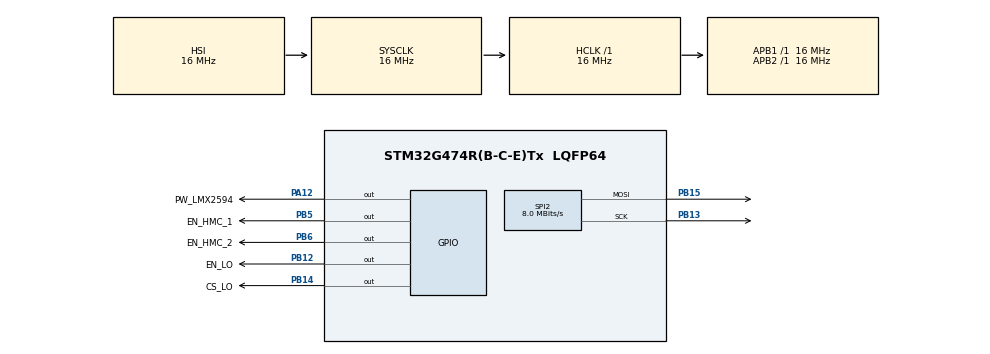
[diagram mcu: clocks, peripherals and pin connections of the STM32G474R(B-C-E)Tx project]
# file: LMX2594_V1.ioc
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Mcu.Family=STM32G4
Mcu.Name=STM32G474R(B-C-E)Tx
Mcu.Package=LQFP64
NVIC.PriorityGroup=NVIC_PRIORITYGROUP_4
PA12.GPIO_Label=PW_LMX2594
PA12.Signal=GPIO_Output
PA13.Mode=JTAG_5_pins
PA13.Signal=SYS_JTMS-SWDIO
PA14.Mode=JTAG_5_pins
PA14.Signal=SYS_JTCK-SWCLK
PA15.Mode=JTAG_5_pins
PA15.Signal=SYS_JTDI
PB12.GPIO_Label=EN_LO
PB12.GPIO_Speed=GPIO_SPEED_FREQ_HIGH
PB12.Signal=GPIO_Output
PB13.Mode=TX_Only_Simplex_Unidirect_Master
PB13.Signal=SPI2_SCK
PB14.GPIO_Label=CS_LO
PB14.GPIO_Speed=GPIO_SPEED_FREQ_HIGH
PB14.Signal=GPIO_Output
PB15.Mode=TX_Only_Simplex_Unidirect_Master
PB15.Signal=SPI2_MOSI
PB3.Mode=JTAG_5_pins
PB3.Signal=SYS_JTDO-SWO
PB4.Mode=JTAG_5_pins
PB4.Signal=SYS_JTRST
PB5.GPIO_Label=EN_HMC_1
PB5.Signal=GPIO_Output
PB6.GPIO_Label=EN_HMC_2
PB6.Signal=GPIO_Output
ProjectManager.HeapSize=0x200
ProjectManager.StackSize=0x400
ProjectManager.TargetToolchain=STM32CubeIDE
RCC.AHBFreq_Value=16000000
RCC.APB1Freq_Value=16000000
RCC.APB1TimFreq_Value=16000000
RCC.APB2Freq_Value=16000000
RCC.APB2TimFreq_Value=16000000
RCC.CortexFreq_Value=16000000
RCC.EXTERNAL_CLOCK_VALUE=12288000
RCC.HCLKFreq_Value=16000000
RCC.HSE_VALUE=8000000
RCC.HSI48_VALUE=48000000
RCC.HSI_VALUE=16000000
RCC.LSE_VALUE=32768
RCC.SYSCLKFreq_VALUE=16000000
RCC.USBFreq_Value=64000000
RCC.VCOOutputFreq_Value=128000000
SPI2.CalculateBaudRate=8.0 MBits/s
SPI2.DataSize=SPI_DATASIZE_8BIT
SPI2.Direction=SPI_DIRECTION_2LINES
SPI2.Mode=SPI_MODE_MASTER
SPI2.VirtualType=VM_MASTER
VP_SYS_VS_DBSignals.Mode=DisableDeadBatterySignals
board=custom

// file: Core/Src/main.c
/* USER CODE BEGIN Header */
/**
  ******************************************************************************
  * @file           : main.c
  * @brief          : Main program body
  ******************************************************************************
  * @attention
  *
  * <h2><center>&copy; Copyright (c) 2025 STMicroelectronics.
  * All rights reserved.</center></h2>
  *
  * This software component is licensed by ST under BSD 3-Clause license,
  * the "License"; You may not use this file except in compliance with the
  * License. You may obtain a copy of the License at:
  *                        opensource.org/licenses/BSD-3-Clause
  *
  ******************************************************************************
  */
/* USER CODE END Header */
#include "main.h"
#include "spi.h"
#include "gpio.h"

/* USER CODE BEGIN Includes */
/*хЕЛП МИ ПЛИЗ*/
/* USER CODE END Includes */

void SystemClock_Config(void);

int main(void)
{

  /* MCU Configuration--------------------------------------------------------*/

  /* Reset of all peripherals, Initializes the Flash interface and the Systick. */
  HAL_Init();

  /* Configure the system clock */
  SystemClock_Config();

  /* Initialize all configured peripherals */
  MX_GPIO_Init();
  MX_SPI2_Init();

  /* Infinite loop */
  while (1)
  {

  }
}

void SystemClock_Config(void)
{
  RCC_OscInitTypeDef RCC_OscInitStruct = {0};
  RCC_ClkInitTypeDef RCC_ClkInitStruct = {0};

  /** Configure the main internal regulator output voltage
  */
  HAL_PWREx_ControlVoltageScaling(PWR_REGULATOR_VOLTAGE_SCALE1);
  /** Initializes the RCC Oscillators according to the specified parameters
  * in the RCC_OscInitTypeDef structure.
  */
  RCC_OscInitStruct.OscillatorType = RCC_OSCILLATORTYPE_HSI;
  RCC_OscInitStruct.HSIState = RCC_HSI_ON;
  RCC_OscInitStruct.HSICalibrationValue = RCC_HSICALIBRATION_DEFAULT;
  RCC_OscInitStruct.PLL.PLLState = RCC_PLL_NONE;
  if (HAL_RCC_OscConfig(&RCC_OscInitStruct) != HAL_OK)
  {
    Error_Handler();
  }
  /** Initializes the CPU, AHB and APB buses clocks
  */
  RCC_ClkInitStruct.ClockType = RCC_CLOCKTYPE_HCLK|RCC_CLOCKTYPE_SYSCLK
                              |RCC_CLOCKTYPE_PCLK1|RCC_CLOCKTYPE_PCLK2;
  RCC_ClkInitStruct.SYSCLKSource = RCC_SYSCLKSOURCE_HSI;
  RCC_ClkInitStruct.AHBCLKDivider = RCC_SYSCLK_DIV1;
  RCC_ClkInitStruct.APB1CLKDivider = RCC_HCLK_DIV1;
  RCC_ClkInitStruct.APB2CLKDivider = RCC_HCLK_DIV1;

  if (HAL_RCC_ClockConfig(&RCC_ClkInitStruct, FLASH_LATENCY_0) != HAL_OK)
  {
    Error_Handler();
  }
}

void Error_Handler(void)
{
  __disable_irq();
  while (1)
  {
  }
}

/************************ (C) COPYRIGHT STMicroelectronics *****END OF FILE****/
